# PIC32MZ1025DAA176 device description
Architecture: MIPS; Family: PIC32MZDA; Series: PIC32MZ
Registers are 32-bit, read-write, no defined reset value unless marked. A register's access mark holds for its fields unless they carry their own. Offsets are from the block's base; [hi:lo] are bit positions; {n}, {i} and the like mark numbered series.

## CVR
Instances: CVR 0x1f800e00 in periph_pb1_std
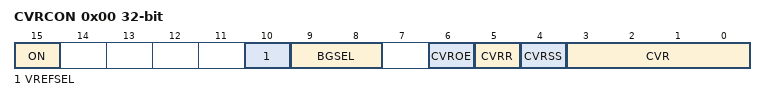
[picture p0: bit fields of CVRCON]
0x00 CVRCON — Comparator Voltage Reference Control Register
  [15] ON — Comparator Voltage Reference On bit
    1=Module is enabled. Setting this bit does not affect other bits in the register.; 0=Module is disabled and does not consume current. Clearing this bit does not affect the other bits in the register.
  [10] VREFSEL
  [9:8] BGSEL
  [6] CVROE — CVrefout Enable bit
    1=Voltage level is output on CVrefout pin; 0=Voltage level is disconnected from CVrefout pin
  [5] CVRR — CVref Range Selection bit
    1=0 to 0.67 CVrsrc; 0=0.25 CVrsrc to 0.75 CVrsrc
  [4] CVRSS — CVref Source Selection bit
    1=Comparator voltage reference source, CVRSRC = (VREF+) - (VREF-); 0=Comparator voltage reference source, CVRSRC = AVDD - AVSS
  [3:0] CVR

## DMT
Instances: DMT 0x1f800a00 in periph_pb1_std
0x00 DMTCON — Deadman Timer Control Register
  [15] ON — Deadman Timer Module Enable bit
    1=Deadman Timer module is enabled; 0=Deadman Timer module is disabled
0x10 DMTPRECLR — Deadman Timer Preclear Register
  [15:8] STEP1 — Preclear Enable bits
    64=Enables the Deadman Timer Preclear (Step 1)
0x20 DMTCLR — Deadman Timer Clear Register
  [7:0] STEP2 — Clear Timer bits
    8=Clears STEP1
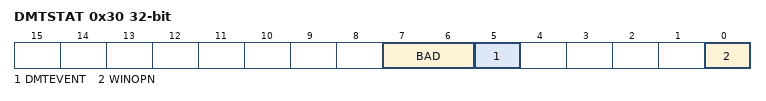
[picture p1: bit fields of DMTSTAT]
0x30 DMTSTAT ro — Deadman Timer Status Register
  [7:6] BAD
  [5] DMTEVENT — Deadman Timer Event bit
    1=Deadman timer event was detected (counter expired or bad STEP1 or STEP2 value was entered prior to counter increment); 0=Deadman timer even was not detected
  [0] WINOPN — Deadman Timer Clear Window bit
    1=Deadman timer clear window is open; 0=Deadman timer clear window is not open
0x40 DMTCNT ro — Deadman Timer Count Register
  [31:0] COUNTER
0x60 DMTPSCNT ro — Post Status Configure DMT Count Status Register
  [31:0] PSCNT
0x70 DMTPSINTV ro — Post Status Configure DMT Interval Status Register
  [31:0] PSINTV
Value list DMTSTAT__BAD2: 64=Incorrect STEP2 value was detected; 0=Incorrect STEP2 value was not detected
Value list DMTSTAT__BAD1: 128=Incorrect STEP1 value or out of sequence write to STEP2 was detected; 0=Incorrect STEP1 value was not detected

## DSCTRL
Instances: DSCTRL 0x1f8c0200 in periph_pb6_std
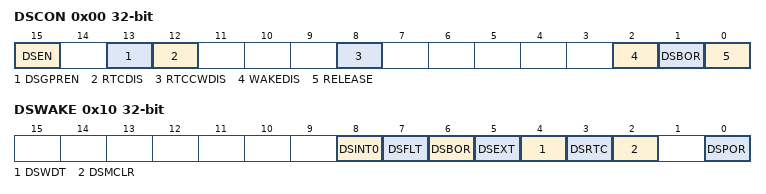
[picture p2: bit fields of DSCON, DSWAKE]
0x00 DSCON
  [15] DSEN, [13] DSGPREN, [12] RTCDIS, [8] RTCCWDIS, [2] WAKEDIS, [1] DSBOR, [0] RELEASE
0x10 DSWAKE
  [8] DSINT0, [7] DSFLT, [6] DSBOR, [5] DSEXT, [4] DSWDT, [3] DSRTC, [2] DSMCLR, [0] DSPOR
0x20 DSGPR0
  [31:0] DSGPR
{0x3C+4i} DSGPR{i} (i=1..32)
  [31:0] DSGPR

## EBI
Instances: EBI 0x1f8e1014 in periph_indep
{0x0+4i} EBICS{i} (i=0..3) — External Bus Interface Chip Select Register
  [31:16] CSADDR — Base Address for Device bits
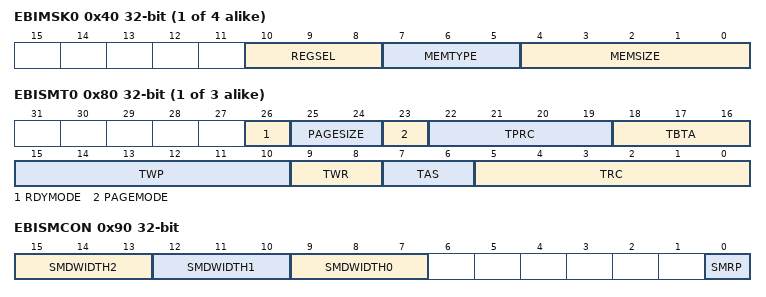
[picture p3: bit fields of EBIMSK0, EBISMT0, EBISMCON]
{0x40+4i} EBIMSK{i} (i=0..3) — External Bus Interface Address Mask Register
  [10:8] REGSEL — Timing Register Set for Chip Select 'x' bits
    2=Use EBISMT2; 1=Use EBISMT1; 0=Use EBISMT0
  [7:5] MEMTYPE — Select Memory Type for Chip Select 'x' bits
    2=NOR-Flash; 1=SRAM
  [4:0] MEMSIZE — Select Memory Size for Chip Select 'x' bits
    9=16 MB; 8=8 MB; 7=4 MB; 6=2 MB; 5=1 MB; 4=512 KB; 3=256 KB; 2=128 KB; 1=64 KB (smaller memories alias within this range); 0=Chip Select is not used
{0x80+4i} EBISMT{i} (i=0..2) — External Bus Interface Static Memory Timing Register
  [26] RDYMODE — Data Ready Device Select bit
    1=EBIRDYx input is used; 0=EBIRDYx input is not used
  [25:24] PAGESIZE — Page Size for Page Mode Device bits
    3=32-word page; 2=16-word page; 1=8-word page; 0=4-word page
  [23] PAGEMODE — Memory Device Page Mode Support bit
    1=Device supports Page mode; 0=Device does not support Page mode
  [22:19] TPRC — Page Mode Read Cycle Time bits
  [18:16] TBTA — Data Bus Turnaround Time bits
  [15:10] TWP — Write Pulse Width bits
  [9:8] TWR — Write Address/Data Hold Time bits
  [7:6] TAS — Write Address Setup Time bits
  [5:0] TRC — Read Cycle Time bits
0x8C EBIFTRPD — External Bus Interface Flash Timing Register
  [31:0] TRPD — Flash Timing bits
0x90 EBISMCON — External Bus Interface Static Memory Control Register
  [15:13] SMDWIDTH2 — Static Memory Width for Register EBISMT2 bits
    4=8 bits; 0=16 bits
  [12:10] SMDWIDTH1 — Static Memory Width for Register EBISMT1 bits
    4=8 bits; 0=16 bits
  [9:7] SMDWIDTH0 — Static Memory Width for Register EBISMT0 bits
    4=8 bits; 0=16 bits
  [0] SMRP — Flash Reset/Power-down mode Select bit
    1=Flash is taken out of Power-down mode; 0=Flash is forced into Power-down mode

## Notices in the file
Copyright (c) 2017 Microchip Technology Inc.
SPDX-License-Identifier: Apache-2.0
Licensed under the Apache License, Version 2.0 (the "License");
you may not use this file except in compliance with the License.
You may obtain a copy of the License at
http://www.apache.org/licenses/LICENSE-2.0
Unless required by applicable law or agreed to in writing, software
distributed under the License is distributed on an "AS IS" BASIS,
WITHOUT WARRANTIES OR CONDITIONS OF ANY KIND, either express or implied.
See the License for the specific language governing permissions and
limitations under the License.
